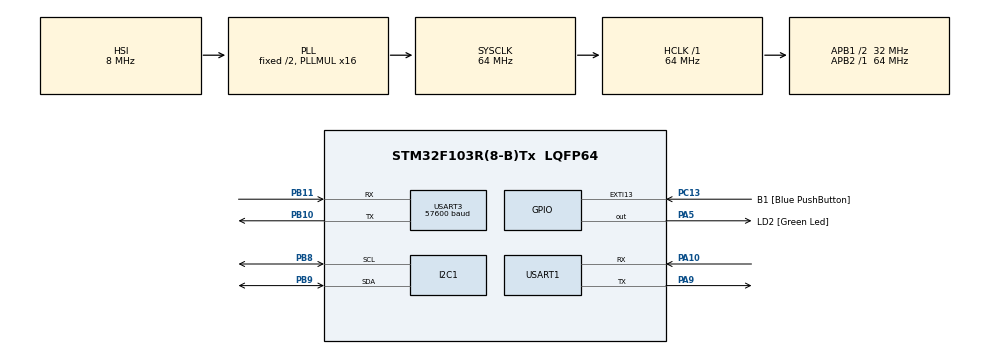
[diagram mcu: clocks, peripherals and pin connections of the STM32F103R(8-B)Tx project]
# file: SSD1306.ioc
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Mcu.Family=STM32F1
NVIC.USART3_IRQn=true\:0\:0\:false\:false\:true\:true\:true
Dma.USART3_RX.0.PeriphInc=DMA_PINC_DISABLE
NVIC.DMA1_Channel5_IRQn=true\:0\:0\:false\:false\:true\:false\:true
NVIC.I2C1_EV_IRQn=true\:0\:0\:false\:false\:true\:true\:true
PB10.Mode=Asynchronous
PA14.GPIO_Label=TCK
PB11.Signal=USART3_RX
RCC.SYSCLKSource=RCC_SYSCLKSOURCE_PLLCLK
ProjectManager.StackSize=0x400
PD1-OSC_OUT.Signal=RCC_OSC_OUT
NVIC.DMA1_Channel3_IRQn=true\:0\:0\:false\:false\:true\:false\:true
USART3.BaudRate=57600
RCC.HCLKFreq_Value=64000000
RCC.APB2TimFreq_Value=64000000
Dma.USART1_RX.1.MemInc=DMA_MINC_ENABLE
RCC.AHBFreq_Value=64000000
NVIC.EXTI15_10_IRQn=true\:0\:0\:false\:false\:true\:true\:true
Dma.USART1_RX.1.PeriphDataAlignment=DMA_PDATAALIGN_BYTE
Dma.USART3_RX.0.MemDataAlignment=DMA_MDATAALIGN_BYTE
RCC.RTCClockSelection=RCC_RTCCLKSOURCE_LSE
RCC.PLLMUL=RCC_PLL_MUL16
PC14-OSC32_IN.Mode=LSE-External-Oscillator
PA14.Mode=Serial_Wire
PA5.GPIO_PuPd=GPIO_NOPULL
NVIC.TIM2_IRQn=true\:0\:0\:false\:false\:true\:true\:true
Dma.USART3_RX.0.PeriphDataAlignment=DMA_PDATAALIGN_BYTE
NVIC.I2C1_ER_IRQn=true\:0\:0\:false\:false\:true\:true\:true
Dma.USART1_RX.1.Mode=DMA_CIRCULAR
Dma.USART3_RX.0.Direction=DMA_PERIPH_TO_MEMORY
PB9.Signal=I2C1_SDA
Mcu.Package=LQFP64
PC13-TAMPER-RTC.GPIO_PuPd=GPIO_NOPULL
PA10.Signal=USART1_RX
Dma.USART3_RX.0.MemInc=DMA_MINC_ENABLE
Dma.USART1_RX.1.PeriphInc=DMA_PINC_DISABLE
Dma.Request1=USART1_RX
RCC.APB1TimFreq_Value=64000000
Dma.USART1_RX.1.Priority=DMA_PRIORITY_LOW
NVIC.USART1_IRQn=true\:0\:0\:false\:false\:true\:true\:true
Dma.Request0=USART3_RX
PB3.GPIO_Label=SWO
Dma.USART3_RX.0.Instance=DMA1_Channel3
PC15-OSC32_OUT.Mode=LSE-External-Oscillator
Dma.USART1_RX.1.Instance=DMA1_Channel5
Dma.USART1_RX.1.MemDataAlignment=DMA_MDATAALIGN_BYTE
PD1-OSC_OUT.Mode=HSE-External-Clock-Source
PA10.Mode=Asynchronous
PC13-TAMPER-RTC.Signal=GPXTI13
PD0-OSC_IN.Signal=RCC_OSC_IN
RCC.APB1CLKDivider=RCC_HCLK_DIV2
PC14-OSC32_IN.Signal=RCC_OSC32_IN
Dma.USART3_RX.0.Mode=DMA_CIRCULAR
PA13.Signal=SYS_JTMS-SWDIO
PA9.Mode=Asynchronous
PB11.Mode=Asynchronous
ProjectManager.TargetToolchain=STM32CubeIDE
I2C1.I2C_Mode=I2C_Fast
PB9.Mode=I2C
PA9.Signal=USART1_TX
RCC.USBFreq_Value=64000000
PC15-OSC32_OUT.Signal=RCC_OSC32_OUT
PD0-OSC_IN.Mode=HSE-External-Clock-Source
PB10.Signal=USART3_TX
PA5.Signal=GPIO_Output
board=NUCLEO-F103RB
PC13-TAMPER-RTC.GPIO_Label=B1 [Blue PushButton]
RCC.APB2Freq_Value=64000000
PA5.GPIO_ModeDefaultOutputPP=GPIO_MODE_OUTPUT_PP
VP_TIM2_VS_ClockSourceINT.Mode=Internal
PA13.Mode=Serial_Wire
Mcu.Name=STM32F103R(8-B)Tx
PA13.GPIO_Label=TMS
PB3.Signal=SYS_JTDO-TRACESWO
RCC.SYSCLKFreq_VALUE=64000000
Dma.USART3_RX.0.Priority=DMA_PRIORITY_LOW
PA5.GPIO_Label=LD2 [Green Led]
USART3.VirtualMode=VM_ASYNC
USART1.VirtualMode=VM_ASYNC
PA14.Signal=SYS_JTCK-SWCLK
ProjectManager.HeapSize=0x200
VP_WWDG_VS_WWDG.Mode=WWDG_Activate
PA5.GPIO_Speed=GPIO_SPEED_FREQ_LOW
NVIC.PriorityGroup=NVIC_PRIORITYGROUP_4
PB8.Mode=I2C
PB8.Signal=I2C1_SCL
Dma.USART1_RX.1.Direction=DMA_PERIPH_TO_MEMORY
RCC.APB1Freq_Value=32000000

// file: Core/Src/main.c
/* USER CODE BEGIN Header */
/**
  ******************************************************************************
  * @file           : main.c
  * @brief          : Main program body
  ******************************************************************************
  * @attention
  *
  * <h2><center>&copy; Copyright (c) 2021 STMicroelectronics.
  * All rights reserved.</center></h2>
  *
  * This software component is licensed by ST under BSD 3-Clause license,
  * the "License"; You may not use this file except in compliance with the
  * License. You may obtain a copy of the License at:
  *                        opensource.org/licenses/BSD-3-Clause
  *
  ******************************************************************************
  */
/* USER CODE END Header */
#include "main.h"
#include "dma.h"
#include "i2c.h"
#include "tim.h"
#include "usart.h"
#include "wwdg.h"
#include "gpio.h"

/* USER CODE BEGIN Includes */
#include <stdio.h>
#include "ssd1306.h"
#include "sh1106.h"
#include "terminal.h"
/* USER CODE END Includes */

/* USER CODE BEGIN PTD */
//uint8_t m_data = 0;
uint8_t font_posX = 0;
uint8_t font_posY = 0;
/* USER CODE END PTD */

void SystemClock_Config(void);

int main(void)
{

  /* MCU Configuration--------------------------------------------------------*/

  /* Reset of all peripherals, Initializes the Flash interface and the Systick. */
  HAL_Init();

  /* Configure the system clock */
  SystemClock_Config();

  /* Initialize all configured peripherals */
  MX_GPIO_Init();
  MX_DMA_Init();
  MX_I2C1_Init();
  MX_USART1_UART_Init();
  MX_USART3_UART_Init();
  MX_TIM2_Init();
  MX_WWDG_Init();
  /* USER CODE BEGIN 2 */
  ssd1306_Init();

//  uint8_t str1[] = "Hello World!\n\r";
//  uint8_t received1 = '\0';
//  HAL_StatusTypeDef rcvStat1;
  printf("Nucleo F103RB Rev 0.1\r\n");
  /* USER CODE END 2 */

  /* Infinite loop */
  while (1)
  {

    /* USER CODE BEGIN 3 */
//	  ssd1306_test();
	  Terminal_Task();
  }
  /* USER CODE END 3 */
}

void SystemClock_Config(void)
{
  RCC_OscInitTypeDef RCC_OscInitStruct = {0};
  RCC_ClkInitTypeDef RCC_ClkInitStruct = {0};

  /** Initializes the RCC Oscillators according to the specified parameters
  * in the RCC_OscInitTypeDef structure.
  */
  RCC_OscInitStruct.OscillatorType = RCC_OSCILLATORTYPE_HSI;
  RCC_OscInitStruct.HSIState = RCC_HSI_ON;
  RCC_OscInitStruct.HSICalibrationValue = RCC_HSICALIBRATION_DEFAULT;
  RCC_OscInitStruct.PLL.PLLState = RCC_PLL_ON;
  RCC_OscInitStruct.PLL.PLLSource = RCC_PLLSOURCE_HSI_DIV2;
  RCC_OscInitStruct.PLL.PLLMUL = RCC_PLL_MUL16;
  if (HAL_RCC_OscConfig(&RCC_OscInitStruct) != HAL_OK)
  {
    Error_Handler();
  }
  /** Initializes the CPU, AHB and APB buses clocks
  */
  RCC_ClkInitStruct.ClockType = RCC_CLOCKTYPE_HCLK|RCC_CLOCKTYPE_SYSCLK
                              |RCC_CLOCKTYPE_PCLK1|RCC_CLOCKTYPE_PCLK2;
  RCC_ClkInitStruct.SYSCLKSource = RCC_SYSCLKSOURCE_PLLCLK;
  RCC_ClkInitStruct.AHBCLKDivider = RCC_SYSCLK_DIV1;
  RCC_ClkInitStruct.APB1CLKDivider = RCC_HCLK_DIV2;
  RCC_ClkInitStruct.APB2CLKDivider = RCC_HCLK_DIV1;

  if (HAL_RCC_ClockConfig(&RCC_ClkInitStruct, FLASH_LATENCY_2) != HAL_OK)
  {
    Error_Handler();
  }
}

void Error_Handler(void)
{
  __disable_irq();
  while (1)
  {
  }
}

/************************ (C) COPYRIGHT STMicroelectronics *****END OF FILE****/
